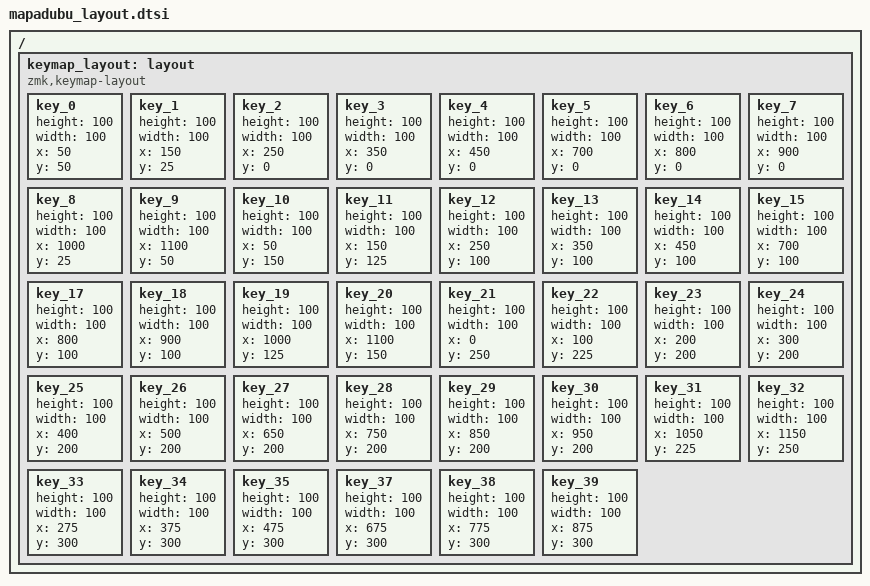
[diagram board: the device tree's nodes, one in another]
/ {
    keymap_layout: layout {
        compatible = "zmk,keymap-layout";

        key_0 {   height = <100>; width = <100>; x = <50>;   y = <50>; };
        key_1 {   height = <100>; width = <100>; x = <150>;  y = <25>; };
        key_2 {   height = <100>; width = <100>; x = <250>;  y = <0>; };
        key_3 {   height = <100>; width = <100>; x = <350>;  y = <0>; };
        key_4 {   height = <100>; width = <100>; x = <450>;  y = <0>; };
        key_5 {   height = <100>; width = <100>; x = <700>;  y = <0>; };
        key_6 {   height = <100>; width = <100>; x = <800>;  y = <0>; };
        key_7 {   height = <100>; width = <100>; x = <900>;  y = <0>; };
        key_8 {   height = <100>; width = <100>; x = <1000>; y = <25>; };
        key_9 {   height = <100>; width = <100>; x = <1100>; y = <50>; };
        key_10 {  height = <100>; width = <100>; x = <50>;   y = <150>; };
        key_11 {  height = <100>; width = <100>; x = <150>;  y = <125>; };
        key_12 {  height = <100>; width = <100>; x = <250>;  y = <100>; };
        key_13 {  height = <100>; width = <100>; x = <350>;  y = <100>; };
        key_14 {  height = <100>; width = <100>; x = <450>;  y = <100>; };
        key_15 {  height = <100>; width = <100>; x = <700>;  y = <100>; };
        // key 16 is missing
        key_17 {  height = <100>; width = <100>; x = <800>;  y = <100>; };
        key_18 {  height = <100>; width = <100>; x = <900>;  y = <100>; };
        key_19 {  height = <100>; width = <100>; x = <1000>; y = <125>; };
        key_20 {  height = <100>; width = <100>; x = <1100>; y = <150>; };
        key_21 {  height = <100>; width = <100>; x = <0>;    y = <250>; };
        key_22 {  height = <100>; width = <100>; x = <100>;  y = <225>; };
        key_23 {  height = <100>; width = <100>; x = <200>;  y = <200>; };
        key_24 {  height = <100>; width = <100>; x = <300>;  y = <200>; };
        key_25 {  height = <100>; width = <100>; x = <400>;  y = <200>; };
        key_26 {  height = <100>; width = <100>; x = <500>;  y = <200>; };
        key_27 {  height = <100>; width = <100>; x = <650>;  y = <200>; };
        key_28 {  height = <100>; width = <100>; x = <750>;  y = <200>; };
        key_29 {  height = <100>; width = <100>; x = <850>;  y = <200>; };
        key_30 {  height = <100>; width = <100>; x = <950>;  y = <200>; };
        key_31 {  height = <100>; width = <100>; x = <1050>; y = <225>; };
        key_32 {  height = <100>; width = <100>; x = <1150>; y = <250>; };
        key_33 {  height = <100>; width = <100>; x = <275>;  y = <300>; };
        key_34 {  height = <100>; width = <100>; x = <375>;  y = <300>; };
        key_35 {  height = <100>; width = <100>; x = <475>;  y = <300>; };
        // key 36 is missing
        key_37 {  height = <100>; width = <100>; x = <675>;  y = <300>; };
        key_38 {  height = <100>; width = <100>; x = <775>;  y = <300>; };
        key_39 {  height = <100>; width = <100>; x = <875>;  y = <300>; };
    };
};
